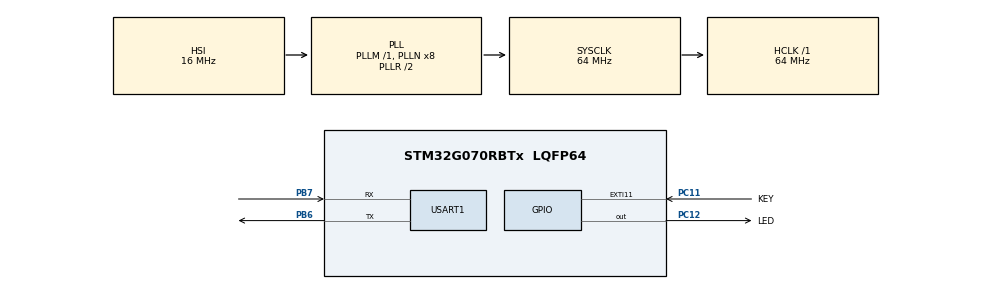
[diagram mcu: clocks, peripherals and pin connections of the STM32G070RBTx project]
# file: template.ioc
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Mcu.Family=STM32G0
Mcu.Name=STM32G070RBTx
Mcu.Package=LQFP64
NVIC.EXTI4_15_IRQn=true\:1\:0\:true\:false\:true\:true\:true\:true
PA13.Mode=Serial_Wire
PA13.Signal=SYS_SWDIO
PA14-BOOT0.Mode=Serial_Wire
PA14-BOOT0.Signal=SYS_SWCLK
PB6.Mode=Asynchronous
PB6.Signal=USART1_TX
PB7.Mode=Asynchronous
PB7.Signal=USART1_RX
PC11.GPIO_Label=KEY
PC11.GPIO_ModeDefaultEXTI=GPIO_MODE_IT_FALLING
PC11.GPIO_PuPd=GPIO_PULLUP
PC11.Signal=GPXTI11
PC12.GPIO_Label=LED
PC12.PinState=GPIO_PIN_SET
PC12.Signal=GPIO_Output
ProjectManager.HeapSize=0x200
ProjectManager.StackSize=0x400
ProjectManager.TargetToolchain=MDK-ARM V5.32
RCC.ADCFreq_Value=64000000
RCC.AHBFreq_Value=64000000
RCC.CortexFreq_Value=64000000
RCC.EXTERNAL_CLOCK_VALUE=48000
RCC.HCLKFreq_Value=64000000
RCC.HSE_VALUE=8000000
RCC.HSI_VALUE=16000000
RCC.LSE_VALUE=32768
RCC.SYSCLKFreq_VALUE=64000000
RCC.SYSCLKSource=RCC_SYSCLKSOURCE_PLLCLK
RCC.VCOOutputFreq_Value=128000000
USART1.VirtualMode-Asynchronous=VM_ASYNC
VP_SYS_VS_DBSignals.Mode=DisableDeadBatterySignals
board=custom

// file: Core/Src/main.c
/* USER CODE BEGIN Header */
/**
  ******************************************************************************
  * @file           : main.c
  * @brief          : Main program body
  ******************************************************************************
  * @attention
  *
  * Copyright (c) 2023 STMicroelectronics.
  * All rights reserved.
  *
  * This software is licensed under terms that can be found in the LICENSE file
  * in the root directory of this software component.
  * If no LICENSE file comes with this software, it is provided AS-IS.
  *
  ******************************************************************************
  */
/* USER CODE END Header */
#include "main.h"
#include "usart.h"
#include "gpio.h"

void SystemClock_Config(void);

int main(void)
{

  /* MCU Configuration--------------------------------------------------------*/

  /* Reset of all peripherals, Initializes the Flash interface and the Systick. */
  HAL_Init();

  /* Configure the system clock */
  SystemClock_Config();

  /* Initialize all configured peripherals */
  MX_GPIO_Init();
  MX_USART1_UART_Init();
  /* USER CODE BEGIN 2 */
  uint8_t i=0;
  for(i=0;i<5;i++){
      //test led
      HAL_GPIO_WritePin(LED_GPIO_Port,LED_Pin,GPIO_PIN_SET);
      HAL_Delay(300);
      HAL_GPIO_WritePin(LED_GPIO_Port,LED_Pin,GPIO_PIN_RESET);
      HAL_Delay(600);
  }
  HAL_GPIO_WritePin(LED_GPIO_Port,LED_Pin,GPIO_PIN_SET);//turn off the led
  /* USER CODE END 2 */

  /* Infinite loop */
  while (1)
  {

    /* USER CODE BEGIN 3 */
    //test uart
    uint8_t test_str[] = "hello MonkeyPi\r\n";
    HAL_UART_Transmit(&huart1,test_str,sizeof(test_str)-1,0xffff);

    HAL_Delay(500);

  }
  /* USER CODE END 3 */
}

void SystemClock_Config(void)
{
  RCC_OscInitTypeDef RCC_OscInitStruct = {0};
  RCC_ClkInitTypeDef RCC_ClkInitStruct = {0};

  /** Configure the main internal regulator output voltage
  */
  HAL_PWREx_ControlVoltageScaling(PWR_REGULATOR_VOLTAGE_SCALE1);

  /** Initializes the RCC Oscillators according to the specified parameters
  * in the RCC_OscInitTypeDef structure.
  */
  RCC_OscInitStruct.OscillatorType = RCC_OSCILLATORTYPE_HSI;
  RCC_OscInitStruct.HSIState = RCC_HSI_ON;
  RCC_OscInitStruct.HSIDiv = RCC_HSI_DIV1;
  RCC_OscInitStruct.HSICalibrationValue = RCC_HSICALIBRATION_DEFAULT;
  RCC_OscInitStruct.PLL.PLLState = RCC_PLL_ON;
  RCC_OscInitStruct.PLL.PLLSource = RCC_PLLSOURCE_HSI;
  RCC_OscInitStruct.PLL.PLLM = RCC_PLLM_DIV1;
  RCC_OscInitStruct.PLL.PLLN = 8;
  RCC_OscInitStruct.PLL.PLLP = RCC_PLLP_DIV2;
  RCC_OscInitStruct.PLL.PLLR = RCC_PLLR_DIV2;
  if (HAL_RCC_OscConfig(&RCC_OscInitStruct) != HAL_OK)
  {
    Error_Handler();
  }

  /** Initializes the CPU, AHB and APB buses clocks
  */
  RCC_ClkInitStruct.ClockType = RCC_CLOCKTYPE_HCLK|RCC_CLOCKTYPE_SYSCLK
                              |RCC_CLOCKTYPE_PCLK1;
  RCC_ClkInitStruct.SYSCLKSource = RCC_SYSCLKSOURCE_PLLCLK;
  RCC_ClkInitStruct.AHBCLKDivider = RCC_SYSCLK_DIV1;
  RCC_ClkInitStruct.APB1CLKDivider = RCC_HCLK_DIV1;

  if (HAL_RCC_ClockConfig(&RCC_ClkInitStruct, FLASH_LATENCY_2) != HAL_OK)
  {
    Error_Handler();
  }
}

/* USER CODE BEGIN 4 */
void HAL_GPIO_EXTI_Falling_Callback(uint16_t GPIO_Pin)
{
  if(HAL_GPIO_ReadPin(KEY_GPIO_Port,KEY_Pin) == 0){
    HAL_GPIO_TogglePin(LED_GPIO_Port,LED_Pin);
  }
}
/* USER CODE END 4 */

void Error_Handler(void)
{
  __disable_irq();
  while (1)
  {
  }
}
